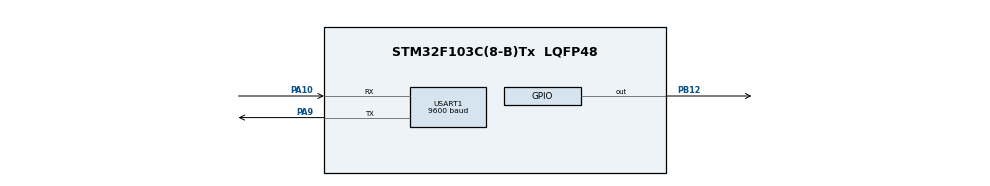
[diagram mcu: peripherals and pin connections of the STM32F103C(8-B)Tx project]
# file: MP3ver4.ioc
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Mcu.Family=STM32F1
Mcu.Name=STM32F103C(8-B)Tx
Mcu.Package=LQFP48
NVIC.PriorityGroup=NVIC_PRIORITYGROUP_4
PA10.Mode=Asynchronous
PA10.Signal=USART1_RX
PA13.Mode=Serial_Wire
PA13.Signal=SYS_JTMS-SWDIO
PA14.Mode=Serial_Wire
PA14.Signal=SYS_JTCK-SWCLK
PA9.Mode=Asynchronous
PA9.Signal=USART1_TX
PB12.Signal=GPIO_Output
ProjectManager.HeapSize=0x200
ProjectManager.StackSize=0x400
ProjectManager.TargetToolchain=MDK-ARM V5.27
RCC.APB1Freq_Value=8000000
RCC.APB2Freq_Value=8000000
USART1.BaudRate=9600
USART1.VirtualMode=VM_ASYNC
board=custom

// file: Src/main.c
/* USER CODE BEGIN Header */
/**
  ******************************************************************************
  * @file           : main.c
  * @brief          : Main program body
  ******************************************************************************
  * @attention
  *
  * <h2><center>&copy; Copyright (c) 2020 STMicroelectronics.
  * All rights reserved.</center></h2>
  *
  * This software component is licensed by ST under BSD 3-Clause license,
  * the "License"; You may not use this file except in compliance with the
  * License. You may obtain a copy of the License at:
  *                        opensource.org/licenses/BSD-3-Clause
  *
  ******************************************************************************
  */
/* USER CODE END Header */

#include "main.h"

/* USER CODE BEGIN PD */
#define MP3_TRAKING_NUM				0x03 // 0..2999
#define MP3_VOLUME					0x06 // 0..30
#define MP3_RESET					0x0C
#define MP3_PLAYBACK				0x0D
#define MP3_PAUSE					0x0E
#define MP3_STOP				0x16

/* USER CODE END PD */

UART_HandleTypeDef huart1;

/* USER CODE BEGIN PV */
uint8_t mp3_cmd_buf[10] = {0x7E, 0xFF, 0x06, 0x00, 0x01, 0x0, 0x0, 0x00, 0x00, 0xEF};

/* USER CODE END PV */

void SystemClock_Config(void);
static void MX_GPIO_Init(void);
static void MX_USART1_UART_Init(void);

/* USER CODE BEGIN PFP */
void MP3_send_cmd (uint8_t cmd, uint16_t high_arg, uint16_t low_arg);
void MP3_stop(void);
void MP3_play(uint8_t index);
void MP3_setVol(uint8_t vol);
/* USER CODE END PFP */

int main(void)
{

  /* MCU Configuration--------------------------------------------------------*/

  /* Reset of all peripherals, Initializes the Flash interface and the Systick. */
  HAL_Init();

  /* Configure the system clock */
  SystemClock_Config();

  /* Initialize all configured peripherals */
  MX_GPIO_Init();
  MX_USART1_UART_Init();
  /* USER CODE BEGIN 2 */
	HAL_Delay(5000);
  /* USER CODE END 2 */

  /* Infinite loop */
  while (1)
  {
		MP3_stop();
		MP3_setVol(30);
		MP3_play(1);
		HAL_Delay(3000);
		MP3_stop();
		HAL_Delay(3000);
		//MP3_setVol(30);
		MP3_play(9);
		HAL_Delay(10000);
  }
}

void SystemClock_Config(void)
{
  RCC_OscInitTypeDef RCC_OscInitStruct = {0};
  RCC_ClkInitTypeDef RCC_ClkInitStruct = {0};

  /** Initializes the CPU, AHB and APB busses clocks
  */
  RCC_OscInitStruct.OscillatorType = RCC_OSCILLATORTYPE_HSI;
  RCC_OscInitStruct.HSIState = RCC_HSI_ON;
  RCC_OscInitStruct.HSICalibrationValue = RCC_HSICALIBRATION_DEFAULT;
  RCC_OscInitStruct.PLL.PLLState = RCC_PLL_NONE;
  if (HAL_RCC_OscConfig(&RCC_OscInitStruct) != HAL_OK)
  {
    Error_Handler();
  }
  /** Initializes the CPU, AHB and APB busses clocks
  */
  RCC_ClkInitStruct.ClockType = RCC_CLOCKTYPE_HCLK|RCC_CLOCKTYPE_SYSCLK
                              |RCC_CLOCKTYPE_PCLK1|RCC_CLOCKTYPE_PCLK2;
  RCC_ClkInitStruct.SYSCLKSource = RCC_SYSCLKSOURCE_HSI;
  RCC_ClkInitStruct.AHBCLKDivider = RCC_SYSCLK_DIV1;
  RCC_ClkInitStruct.APB1CLKDivider = RCC_HCLK_DIV1;
  RCC_ClkInitStruct.APB2CLKDivider = RCC_HCLK_DIV1;

  if (HAL_RCC_ClockConfig(&RCC_ClkInitStruct, FLASH_LATENCY_0) != HAL_OK)
  {
    Error_Handler();
  }
}

static void MX_USART1_UART_Init(void)
{

  huart1.Instance = USART1;
  huart1.Init.BaudRate = 9600;
  huart1.Init.WordLength = UART_WORDLENGTH_8B;
  huart1.Init.StopBits = UART_STOPBITS_1;
  huart1.Init.Parity = UART_PARITY_NONE;
  huart1.Init.Mode = UART_MODE_TX_RX;
  huart1.Init.HwFlowCtl = UART_HWCONTROL_NONE;
  huart1.Init.OverSampling = UART_OVERSAMPLING_16;
  if (HAL_UART_Init(&huart1) != HAL_OK)
  {
    Error_Handler();
  }

}

static void MX_GPIO_Init(void)
{
  GPIO_InitTypeDef GPIO_InitStruct = {0};

  /* GPIO Ports Clock Enable */
  __HAL_RCC_GPIOB_CLK_ENABLE();
  __HAL_RCC_GPIOA_CLK_ENABLE();

  /*Configure GPIO pin Output Level */
  HAL_GPIO_WritePin(GPIOB, GPIO_PIN_12, GPIO_PIN_RESET);

  /*Configure GPIO pin : PB12 */
  GPIO_InitStruct.Pin = GPIO_PIN_12;
  GPIO_InitStruct.Mode = GPIO_MODE_OUTPUT_PP;
  GPIO_InitStruct.Pull = GPIO_NOPULL;
  GPIO_InitStruct.Speed = GPIO_SPEED_FREQ_LOW;
  HAL_GPIO_Init(GPIOB, &GPIO_InitStruct);

}

void Error_Handler(void)
{
}

/************************ (C) COPYRIGHT STMicroelectronics *****END OF FILE****/
/* Calculate checksum
 */
uint16_t MP3_checksum (void) {
	uint16_t sum = 0;
	uint8_t i;
	for (i=1; i<7; i++) {
		sum += mp3_cmd_buf[i];
	}
	return -sum;
}

/* Send command to DFPlayer
 */
void MP3_send_cmd (uint8_t cmd, uint16_t high_arg, uint16_t low_arg) {
	HAL_GPIO_TogglePin(GPIOB,GPIO_PIN_12);
	HAL_Delay(100);
	HAL_GPIO_TogglePin(GPIOB,GPIO_PIN_12);

	uint16_t checksum;

	mp3_cmd_buf[3] = cmd;

	mp3_cmd_buf[5] = high_arg;
	mp3_cmd_buf[6] = low_arg;

	checksum = MP3_checksum();
	mp3_cmd_buf[7] = (uint8_t) ((checksum >> 8) & 0x00FF);
	mp3_cmd_buf[8] = (uint8_t) (checksum & 0x00FF);

	// Send command to UART3
	/*
	for (i=0; i<10; i++) {
		char* data = &mp3_cmd_buf[0];
		int size = sizeof(mp3_cmd_buf);
		HAL_UART_Transmit(&huart3,data,size,1000);
//        USART_SendData(USART3, mp3_cmd_buf[i]);
//        while(USART_GetFlagStatus(USART3, USART_FLAG_TC) == RESET)
				{
				}
		}
		*/
		int size = sizeof(mp3_cmd_buf);
		HAL_StatusTypeDef status = HAL_ERROR;
		uint8_t i = 0;
		while((status != HAL_OK) || i <= 10)
			{
				status = HAL_UART_Transmit(&huart1,&mp3_cmd_buf[0],size,300);
				i++;
		}
		//memset(&mp3_cmd_buf[0], 0, sizeof mp3_cmd_buf);
}
void MP3_stop(void)
{

	MP3_send_cmd(MP3_STOP,0,0);
}

void MP3_play(uint8_t index)
{
	MP3_send_cmd(MP3_STOP,0,0);
	MP3_send_cmd(MP3_TRAKING_NUM,0,index);
}
void MP3_setVol(uint8_t vol)
{
	MP3_send_cmd(MP3_VOLUME,0,vol);
}
